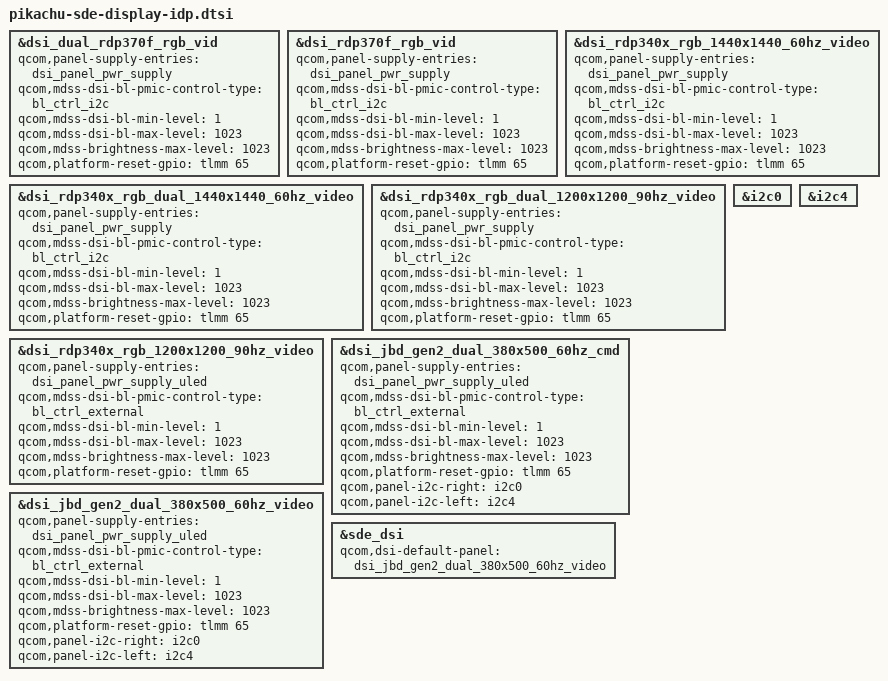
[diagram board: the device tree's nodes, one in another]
// SPDX-License-Identifier: BSD-3-Clause
/*
 * Copyright (c) Qualcomm Technologies, Inc. and/or its subsidiaries.
 */

#include "pikachu-sde-display.dtsi"

&dsi_dual_rdp370f_rgb_vid {
	qcom,panel-supply-entries = <&dsi_panel_pwr_supply>;
	qcom,mdss-dsi-bl-pmic-control-type = "bl_ctrl_i2c";
	qcom,mdss-dsi-bl-min-level = <1>;
	qcom,mdss-dsi-bl-max-level = <1023>;
	qcom,mdss-brightness-max-level = <1023>;
	qcom,platform-reset-gpio = <&tlmm 65 0>;
};

&dsi_rdp370f_rgb_vid {
	qcom,panel-supply-entries = <&dsi_panel_pwr_supply>;
	qcom,mdss-dsi-bl-pmic-control-type = "bl_ctrl_i2c";
	qcom,mdss-dsi-bl-min-level = <1>;
	qcom,mdss-dsi-bl-max-level = <1023>;
	qcom,mdss-brightness-max-level = <1023>;
	qcom,platform-reset-gpio = <&tlmm 65 0>;
};

&dsi_rdp340x_rgb_dual_1440x1440_60hz_video {
	qcom,panel-supply-entries = <&dsi_panel_pwr_supply>;
	qcom,mdss-dsi-bl-pmic-control-type = "bl_ctrl_i2c";
	qcom,mdss-dsi-bl-min-level = <1>;
	qcom,mdss-dsi-bl-max-level = <1023>;
	qcom,mdss-brightness-max-level = <1023>;
	qcom,platform-reset-gpio = <&tlmm 65 0>;
};

&dsi_rdp340x_rgb_1440x1440_60hz_video {
	qcom,panel-supply-entries = <&dsi_panel_pwr_supply>;
	qcom,mdss-dsi-bl-pmic-control-type = "bl_ctrl_i2c";
	qcom,mdss-dsi-bl-min-level = <1>;
	qcom,mdss-dsi-bl-max-level = <1023>;
	qcom,mdss-brightness-max-level = <1023>;
	qcom,platform-reset-gpio = <&tlmm 65 0>;
};

&dsi_rdp340x_rgb_dual_1200x1200_90hz_video {
	qcom,panel-supply-entries = <&dsi_panel_pwr_supply>;
	qcom,mdss-dsi-bl-pmic-control-type = "bl_ctrl_i2c";
	qcom,mdss-dsi-bl-min-level = <1>;
	qcom,mdss-dsi-bl-max-level = <1023>;
	qcom,mdss-brightness-max-level = <1023>;
	qcom,platform-reset-gpio = <&tlmm 65 0>;
};

&dsi_rdp340x_rgb_1200x1200_90hz_video {
	qcom,panel-supply-entries = <&dsi_panel_pwr_supply_uled>;
	qcom,mdss-dsi-bl-pmic-control-type = "bl_ctrl_external";
	qcom,mdss-dsi-bl-min-level = <1>;
	qcom,mdss-dsi-bl-max-level = <1023>;
	qcom,mdss-brightness-max-level = <1023>;
	qcom,platform-reset-gpio = <&tlmm 65 0>;
};

&dsi_jbd_gen2_dual_380x500_60hz_cmd {
	qcom,panel-supply-entries = <&dsi_panel_pwr_supply_uled>;
	qcom,mdss-dsi-bl-pmic-control-type = "bl_ctrl_external";
	qcom,mdss-dsi-bl-min-level = <1>;
	qcom,mdss-dsi-bl-max-level = <1023>;
	qcom,mdss-brightness-max-level = <1023>;
	qcom,platform-reset-gpio = <&tlmm 65 0>;
	qcom,panel-i2c-right = <&i2c0>;
	qcom,panel-i2c-left = <&i2c4>;
};

&dsi_jbd_gen2_dual_380x500_60hz_video {
	qcom,panel-supply-entries = <&dsi_panel_pwr_supply_uled>;
	qcom,mdss-dsi-bl-pmic-control-type = "bl_ctrl_external";
	qcom,mdss-dsi-bl-min-level = <1>;
	qcom,mdss-dsi-bl-max-level = <1023>;
	qcom,mdss-brightness-max-level = <1023>;
	qcom,platform-reset-gpio = <&tlmm 65 0>;
	qcom,panel-i2c-right = <&i2c0>;
	qcom,panel-i2c-left = <&i2c4>;
};

&sde_dsi {
	qcom,dsi-default-panel = <&dsi_jbd_gen2_dual_380x500_60hz_video>;
};

&i2c0 {
	status = "ok";
};

&i2c4 {
	status = "ok";
};
